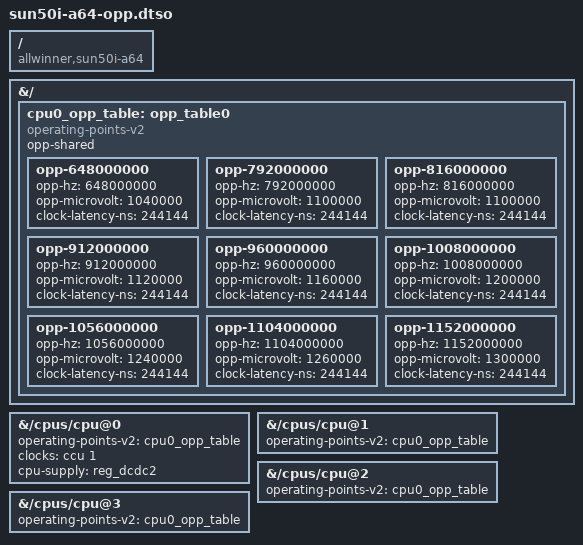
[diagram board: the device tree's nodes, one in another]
/dts-v1/;
/plugin/;

/ {
	compatible = "allwinner,sun50i-a64";
};

&{/} {
	cpu0_opp_table: opp_table0 {
		compatible = "operating-points-v2";
		opp-shared;

		opp-648000000 {
			opp-hz = /bits/ 64 <648000000>;
			opp-microvolt = <1040000>;
			clock-latency-ns = <244144>; /* 8 32k periods */
		};
		opp-792000000 {
			opp-hz = /bits/ 64 <792000000>;
			opp-microvolt = <1100000>;
			clock-latency-ns = <244144>; /* 8 32k periods */
		};
		opp-816000000 {
			opp-hz = /bits/ 64 <816000000>;
			opp-microvolt = <1100000>;
			clock-latency-ns = <244144>; /* 8 32k periods */
		};
		opp-912000000 {
			opp-hz = /bits/ 64 <912000000>;
			opp-microvolt = <1120000>;
			clock-latency-ns = <244144>; /* 8 32k periods */
		};
		opp-960000000 {
			opp-hz = /bits/ 64 <960000000>;
			opp-microvolt = <1160000>;
			clock-latency-ns = <244144>; /* 8 32k periods */
		};
		opp-1008000000 {
			opp-hz = /bits/ 64 <1008000000>;
			opp-microvolt = <1200000>;
			clock-latency-ns = <244144>; /* 8 32k periods */
		};
		opp-1056000000 {
			opp-hz = /bits/ 64 <1056000000>;
			opp-microvolt = <1240000>;
			clock-latency-ns = <244144>; /* 8 32k periods */
		};
		opp-1104000000 {
			opp-hz = /bits/ 64 <1104000000>;
			opp-microvolt = <1260000>;
			clock-latency-ns = <244144>; /* 8 32k periods */
		};
		opp-1152000000 {
			opp-hz = /bits/ 64 <1152000000>;
			opp-microvolt = <1300000>;
			clock-latency-ns = <244144>; /* 8 32k periods */
		};
	};
};

&{/cpus/cpu@0} {
	operating-points-v2 = <&cpu0_opp_table>;
	clocks = <&ccu 1>;
	cpu-supply = <&reg_dcdc2>;
};

&{/cpus/cpu@1} {
	operating-points-v2 = <&cpu0_opp_table>;
};

&{/cpus/cpu@2} {
	operating-points-v2 = <&cpu0_opp_table>;
};

&{/cpus/cpu@3} {
	operating-points-v2 = <&cpu0_opp_table>;
};
